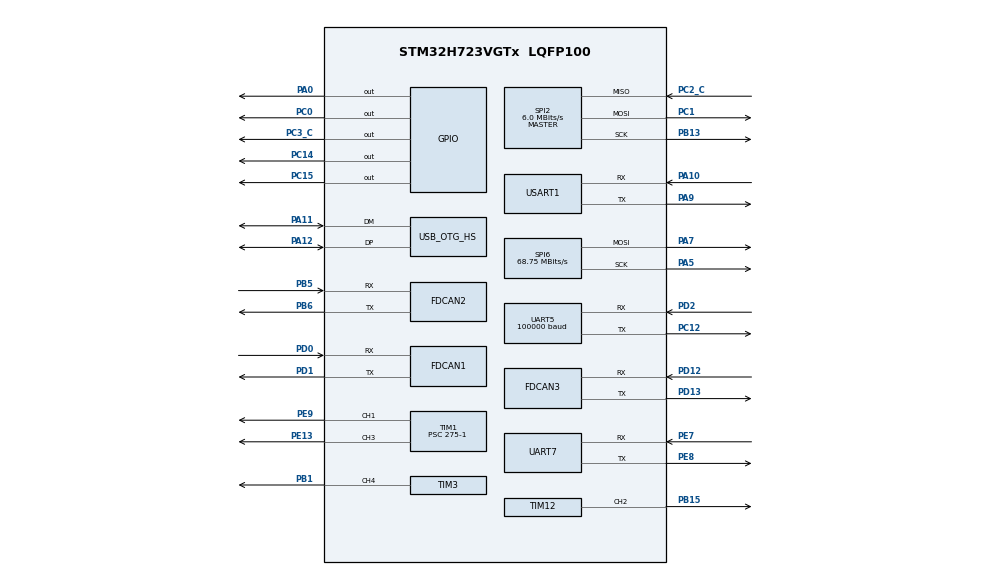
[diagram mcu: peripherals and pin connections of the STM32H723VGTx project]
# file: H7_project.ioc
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Bdma.Request0=SPI6_TX
Bdma.RequestsNb=1
Bdma.SPI6_TX.0.Direction=DMA_MEMORY_TO_PERIPH
Bdma.SPI6_TX.0.EventEnable=DISABLE
Bdma.SPI6_TX.0.Instance=BDMA_Channel0
Bdma.SPI6_TX.0.MemDataAlignment=DMA_MDATAALIGN_BYTE
Bdma.SPI6_TX.0.MemInc=DMA_MINC_ENABLE
Bdma.SPI6_TX.0.Mode=DMA_NORMAL
Bdma.SPI6_TX.0.PeriphDataAlignment=DMA_PDATAALIGN_BYTE
Bdma.SPI6_TX.0.PeriphInc=DMA_PINC_DISABLE
Bdma.SPI6_TX.0.Polarity=HAL_DMAMUX_REQ_GEN_RISING
Bdma.SPI6_TX.0.Priority=DMA_PRIORITY_VERY_HIGH
Bdma.SPI6_TX.0.RequestNumber=1
Bdma.SPI6_TX.0.SignalID=NONE
Bdma.SPI6_TX.0.SyncEnable=DISABLE
Bdma.SPI6_TX.0.SyncPolarity=HAL_DMAMUX_SYNC_NO_EVENT
Bdma.SPI6_TX.0.SyncRequestNumber=1
Bdma.SPI6_TX.0.SyncSignalID=NONE
CORTEX_M7.default_mode_Activation=1
Dma.Request0=UART5_RX
Dma.Request1=USART1_RX
Dma.Request2=USART1_TX
Dma.Request3=UART7_RX
Dma.Request4=UART7_TX
Dma.UART5_RX.0.Direction=DMA_PERIPH_TO_MEMORY
Dma.UART5_RX.0.EventEnable=DISABLE
Dma.UART5_RX.0.FIFOMode=DMA_FIFOMODE_DISABLE
Dma.UART5_RX.0.Instance=DMA1_Stream0
Dma.UART5_RX.0.MemDataAlignment=DMA_MDATAALIGN_BYTE
Dma.UART5_RX.0.MemInc=DMA_MINC_ENABLE
Dma.UART5_RX.0.Mode=DMA_CIRCULAR
Dma.UART5_RX.0.PeriphDataAlignment=DMA_PDATAALIGN_BYTE
Dma.UART5_RX.0.PeriphInc=DMA_PINC_DISABLE
Dma.UART5_RX.0.Polarity=HAL_DMAMUX_REQ_GEN_RISING
Dma.UART5_RX.0.Priority=DMA_PRIORITY_VERY_HIGH
Dma.UART5_RX.0.RequestNumber=1
Dma.UART5_RX.0.SignalID=NONE
Dma.UART5_RX.0.SyncEnable=DISABLE
Dma.UART5_RX.0.SyncPolarity=HAL_DMAMUX_SYNC_NO_EVENT
Dma.UART5_RX.0.SyncRequestNumber=1
Dma.UART5_RX.0.SyncSignalID=NONE
Dma.UART7_RX.3.Direction=DMA_PERIPH_TO_MEMORY
Dma.UART7_RX.3.EventEnable=DISABLE
Dma.UART7_RX.3.FIFOMode=DMA_FIFOMODE_DISABLE
Dma.UART7_RX.3.Instance=DMA1_Stream1
Dma.UART7_RX.3.MemDataAlignment=DMA_MDATAALIGN_BYTE
Dma.UART7_RX.3.MemInc=DMA_MINC_ENABLE
Dma.UART7_RX.3.Mode=DMA_CIRCULAR
Dma.UART7_RX.3.PeriphDataAlignment=DMA_PDATAALIGN_BYTE
Dma.UART7_RX.3.PeriphInc=DMA_PINC_DISABLE
Dma.UART7_RX.3.Polarity=HAL_DMAMUX_REQ_GEN_RISING
Dma.UART7_RX.3.Priority=DMA_PRIORITY_LOW
Dma.UART7_RX.3.RequestNumber=1
Dma.UART7_RX.3.SignalID=NONE
Dma.UART7_RX.3.SyncEnable=DISABLE
Dma.UART7_RX.3.SyncPolarity=HAL_DMAMUX_SYNC_NO_EVENT
Dma.UART7_RX.3.SyncRequestNumber=1
Dma.UART7_RX.3.SyncSignalID=NONE
Dma.UART7_TX.4.Direction=DMA_MEMORY_TO_PERIPH
Dma.UART7_TX.4.EventEnable=DISABLE
Dma.UART7_TX.4.FIFOMode=DMA_FIFOMODE_DISABLE
Dma.UART7_TX.4.Instance=DMA1_Stream3
Dma.UART7_TX.4.MemDataAlignment=DMA_MDATAALIGN_BYTE
Dma.UART7_TX.4.MemInc=DMA_MINC_ENABLE
Dma.UART7_TX.4.Mode=DMA_NORMAL
Dma.UART7_TX.4.PeriphDataAlignment=DMA_PDATAALIGN_BYTE
Dma.UART7_TX.4.PeriphInc=DMA_PINC_DISABLE
Dma.UART7_TX.4.Polarity=HAL_DMAMUX_REQ_GEN_RISING
Dma.UART7_TX.4.Priority=DMA_PRIORITY_LOW
Dma.UART7_TX.4.RequestNumber=1
Dma.UART7_TX.4.SignalID=NONE
Dma.UART7_TX.4.SyncEnable=DISABLE
Dma.UART7_TX.4.SyncPolarity=HAL_DMAMUX_SYNC_NO_EVENT
Dma.UART7_TX.4.SyncRequestNumber=1
Dma.UART7_TX.4.SyncSignalID=NONE
Dma.USART1_RX.1.Direction=DMA_PERIPH_TO_MEMORY
Dma.USART1_RX.1.EventEnable=DISABLE
Dma.USART1_RX.1.FIFOMode=DMA_FIFOMODE_DISABLE
Dma.USART1_RX.1.Instance=DMA1_Stream2
Dma.USART1_RX.1.MemDataAlignment=DMA_MDATAALIGN_BYTE
Dma.USART1_RX.1.MemInc=DMA_MINC_ENABLE
Dma.USART1_RX.1.Mode=DMA_CIRCULAR
Dma.USART1_RX.1.PeriphDataAlignment=DMA_PDATAALIGN_BYTE
Dma.USART1_RX.1.PeriphInc=DMA_PINC_DISABLE
Dma.USART1_RX.1.Polarity=HAL_DMAMUX_REQ_GEN_RISING
Dma.USART1_RX.1.Priority=DMA_PRIORITY_VERY_HIGH
Dma.USART1_RX.1.RequestNumber=1
Dma.USART1_RX.1.SignalID=NONE
Dma.USART1_RX.1.SyncEnable=DISABLE
Dma.USART1_RX.1.SyncPolarity=HAL_DMAMUX_SYNC_NO_EVENT
Dma.USART1_RX.1.SyncRequestNumber=1
Dma.USART1_RX.1.SyncSignalID=NONE
Dma.USART1_TX.2.Direction=DMA_MEMORY_TO_PERIPH
Dma.USART1_TX.2.EventEnable=DISABLE
Dma.USART1_TX.2.FIFOMode=DMA_FIFOMODE_DISABLE
Dma.USART1_TX.2.Instance=DMA1_Stream4
Dma.USART1_TX.2.MemDataAlignment=DMA_MDATAALIGN_BYTE
Dma.USART1_TX.2.MemInc=DMA_MINC_ENABLE
Dma.USART1_TX.2.Mode=DMA_NORMAL
Dma.USART1_TX.2.PeriphDataAlignment=DMA_PDATAALIGN_BYTE
Dma.USART1_TX.2.PeriphInc=DMA_PINC_DISABLE
Dma.USART1_TX.2.Polarity=HAL_DMAMUX_REQ_GEN_RISING
Dma.USART1_TX.2.Priority=DMA_PRIORITY_HIGH
Dma.USART1_TX.2.RequestNumber=1
Dma.USART1_TX.2.SignalID=NONE
Dma.USART1_TX.2.SyncEnable=DISABLE
Dma.USART1_TX.2.SyncPolarity=HAL_DMAMUX_SYNC_NO_EVENT
Dma.USART1_TX.2.SyncRequestNumber=1
Dma.USART1_TX.2.SyncSignalID=NONE
FDCAN1.CalculateBaudRateNominal=1000000
FDCAN1.CalculateTimeBitNominal=1000
FDCAN1.CalculateTimeQuantumNominal=62.5
FDCAN1.DataPrescaler=3
FDCAN1.DataTimeSeg1=7
FDCAN1.DataTimeSeg2=8
FDCAN1.NominalPrescaler=3
FDCAN1.NominalTimeSeg1=7
FDCAN1.NominalTimeSeg2=8
FDCAN1.RxFifo0ElmtsNbr=8
FDCAN1.StdFiltersNbr=1
FDCAN1.TxFifoQueueElmtsNbr=8
FDCAN2.CalculateBaudRateNominal=1000000
FDCAN2.CalculateTimeBitNominal=1000
FDCAN2.CalculateTimeQuantumNominal=62.5
FDCAN2.DataPrescaler=3
FDCAN2.DataTimeSeg1=7
FDCAN2.DataTimeSeg2=8
FDCAN2.MessageRAMOffset=800
FDCAN2.NominalPrescaler=3
FDCAN2.NominalTimeSeg1=7
FDCAN2.NominalTimeSeg2=8
FDCAN2.RxFifo0ElmtsNbr=8
FDCAN2.StdFiltersNbr=1
FDCAN2.TxFifoQueueElmtsNbr=8
FDCAN3.CalculateBaudRateNominal=1000000
FDCAN3.CalculateTimeBitNominal=1000
FDCAN3.CalculateTimeQuantumNominal=62.5
FDCAN3.DataPrescaler=3
FDCAN3.DataTimeSeg1=7
FDCAN3.DataTimeSeg2=8
FDCAN3.MessageRAMOffset=1600
FDCAN3.NominalPrescaler=3
FDCAN3.NominalTimeSeg1=7
FDCAN3.NominalTimeSeg2=8
FDCAN3.RxFifo1ElmtsNbr=8
FDCAN3.StdFiltersNbr=1
FDCAN3.TxFifoQueueElmtsNbr=8
Mcu.Family=STM32H7
Mcu.Name=STM32H723VGTx
Mcu.Package=LQFP100
NVIC.BDMA_Channel0_IRQn=true\:0\:0\:false\:false\:true\:false\:true\:true
NVIC.DMA1_Stream0_IRQn=true\:0\:0\:false\:false\:true\:false\:true\:true
NVIC.DMA1_Stream1_IRQn=true\:0\:0\:false\:false\:true\:false\:true\:true
NVIC.DMA1_Stream2_IRQn=true\:0\:0\:false\:false\:true\:false\:true\:true
NVIC.DMA1_Stream3_IRQn=true\:0\:0\:false\:false\:true\:false\:true\:true
NVIC.DMA1_Stream4_IRQn=true\:0\:0\:false\:false\:true\:false\:true\:true
NVIC.FDCAN1_IT0_IRQn=true\:1\:0\:true\:false\:true\:true\:true\:true
NVIC.FDCAN2_IT0_IRQn=true\:1\:0\:true\:false\:true\:true\:true\:true
NVIC.FDCAN3_IT1_IRQn=true\:1\:0\:true\:false\:true\:true\:true\:true
NVIC.OTG_HS_IRQn=true\:0\:0\:false\:false\:true\:true\:true\:true
NVIC.PriorityGroup=NVIC_PRIORITYGROUP_4
NVIC.SPI6_IRQn=true\:0\:0\:false\:false\:true\:false\:true\:true
NVIC.TIM2_IRQn=true\:0\:0\:false\:false\:true\:true\:true\:true
NVIC.TIM6_DAC_IRQn=true\:2\:0\:true\:false\:true\:true\:true\:true
NVIC.UART5_IRQn=true\:0\:0\:false\:false\:true\:true\:true\:true
NVIC.UART7_IRQn=true\:0\:0\:false\:false\:true\:true\:true\:true
NVIC.USART1_IRQn=true\:0\:0\:false\:false\:true\:false\:true\:true
PA0.Signal=GPIO_Output
PA10.Mode=Asynchronous
PA10.Signal=USART1_RX
PA11.Mode=Device_Only_FS
PA11.Signal=USB_OTG_HS_DM
PA12.Mode=Device_Only_FS
PA12.Signal=USB_OTG_HS_DP
PA13(JTMS/SWDIO).Mode=Serial_Wire
PA13(JTMS/SWDIO).Signal=DEBUG_JTMS-SWDIO
PA14(JTCK/SWCLK).Mode=Serial_Wire
PA14(JTCK/SWCLK).Signal=DEBUG_JTCK-SWCLK
PA5.Mode=TX_Only_Simplex_Unidirect_Master
PA5.Signal=SPI6_SCK
PA7.Mode=TX_Only_Simplex_Unidirect_Master
PA7.Signal=SPI6_MOSI
PA9.Mode=Asynchronous
PA9.Signal=USART1_TX
PB1.Signal=S_TIM3_CH4
PB13.Mode=Full_Duplex_Master
PB13.Signal=SPI2_SCK
PB15.Signal=S_TIM12_CH2
PB5.Mode=FDCAN_Activate
PB5.Signal=FDCAN2_RX
PB6.Mode=FDCAN_Activate
PB6.Signal=FDCAN2_TX
PC0.GPIO_Speed=GPIO_SPEED_FREQ_VERY_HIGH
PC0.Signal=GPIO_Output
PC1.Mode=Full_Duplex_Master
PC1.Signal=SPI2_MOSI
PC12.Mode=Asynchronous
PC12.Signal=UART5_TX
PC14-OSC32_IN.Signal=GPIO_Output
PC15-OSC32_OUT.Signal=GPIO_Output
PC2_C.Mode=Full_Duplex_Master
PC2_C.Signal=SPI2_MISO
PC3_C.GPIO_Speed=GPIO_SPEED_FREQ_VERY_HIGH
PC3_C.Signal=GPIO_Output
PD0.Mode=FDCAN_Activate
PD0.Signal=FDCAN1_RX
PD1.Mode=FDCAN_Activate
PD1.Signal=FDCAN1_TX
PD12.Mode=FDCAN_Activate
PD12.Signal=FDCAN3_RX
PD13.Mode=FDCAN_Activate
PD13.Signal=FDCAN3_TX
PD2.Mode=Asynchronous
PD2.Signal=UART5_RX
PE13.Signal=S_TIM1_CH3
PE7.Mode=Asynchronous
PE7.Signal=UART7_RX
PE8.Mode=Asynchronous
PE8.Signal=UART7_TX
PE9.Signal=S_TIM1_CH1
PH0-OSC_IN.Mode=HSE-External-Oscillator
PH0-OSC_IN.Signal=RCC_OSC_IN
PH1-OSC_OUT.Mode=HSE-External-Oscillator
PH1-OSC_OUT.Signal=RCC_OSC_OUT
ProjectManager.HeapSize=0x800
ProjectManager.StackSize=0x800
ProjectManager.TargetToolchain=CMake
RCC.ADCFreq_Value=96000000
RCC.APB1Freq_Value=137500000
RCC.APB2Freq_Value=137500000
RCC.APB3Freq_Value=137500000
RCC.APB4Freq_Value=137500000
RCC.CortexFreq_Value=550000000
RCC.D1PPRE=RCC_APB3_DIV2
RCC.D2PPRE1=RCC_APB1_DIV2
RCC.D2PPRE2=RCC_APB2_DIV2
RCC.D3PPRE=RCC_APB4_DIV2
RCC.DIVM1=3
RCC.DIVM2=16
RCC.DIVM3=16
RCC.DIVN1=68
RCC.DIVN2=128
RCC.DIVN3=128
RCC.DIVP1=1
RCC.DIVQ2=4
RCC.DIVQ3=4
RCC.FDCANCLockSelection=RCC_FDCANCLKSOURCE_PLL2
RCC.HCLKFreq_Value=275000000
RCC.HPRE=RCC_HCLK_DIV2
RCC.HSE_VALUE=24000000
RCC.PLL2FRACN=0
RCC.PLLFRACN=6144
RCC.PLLSourceVirtual=RCC_PLLSOURCE_HSE
RCC.SPI123CLockSelection=RCC_SPI123CLKSOURCE_PLL2
RCC.SYSCLKFreq_VALUE=550000000
RCC.SYSCLKSource=RCC_SYSCLKSOURCE_PLLCLK
RCC.USART234578CLockSelection=RCC_USART234578CLKSOURCE_PLL2
RCC.USBCLockSelection=RCC_USBCLKSOURCE_PLL3
RCC.USBFreq_Value=48000000
SH.S_TIM12_CH2.0=TIM12_CH2,PWM Generation2 CH2
SH.S_TIM1_CH1.0=TIM1_CH1,PWM Generation1 CH1
SH.S_TIM1_CH3.0=TIM1_CH3,PWM Generation3 CH3
SH.S_TIM3_CH4.0=TIM3_CH4,Output Compare4 CH4
SPI2.BaudRatePrescaler=SPI_BAUDRATEPRESCALER_16
SPI2.CalculateBaudRate=6.0 MBits/s
SPI2.DataSize=SPI_DATASIZE_8BIT
SPI2.Direction=SPI_DIRECTION_2LINES
SPI2.Mode=SPI_MODE_MASTER
SPI2.VirtualType=VM_MASTER
SPI6.CalculateBaudRate=68.75 MBits/s
SPI6.Direction=SPI_DIRECTION_2LINES_TXONLY
SPI6.Mode=SPI_MODE_MASTER
SPI6.VirtualType=VM_MASTER
TIM1.Channel-PWM\ Generation1\ CH1=TIM_CHANNEL_1
TIM1.Channel-PWM\ Generation3\ CH3=TIM_CHANNEL_3
TIM1.Period=500-1
TIM1.Prescaler=275-1
TIM12.Channel-PWM\ Generation2\ CH2=TIM_CHANNEL_2
TIM12.Period=1000-1
TIM12.Prescaler=275-1
TIM2.AutoReloadPreload=TIM_AUTORELOAD_PRELOAD_DISABLE
TIM2.Period=275-1
TIM2.Prescaler=1000-1
TIM3.Channel-Output\ Compare4\ CH4=TIM_CHANNEL_4
TIM6.Period=1000-1
TIM6.Prescaler=275-1
UART5.BaudRate=100000
UART5.Mode=MODE_RX
UART5.Parity=PARITY_EVEN
UART5.WordLength=WORDLENGTH_9B
USART1.VirtualMode-Asynchronous=VM_ASYNC
USB_DEVICE.CLASS_NAME_HS=CDC
USB_DEVICE.VirtualMode=Cdc
USB_DEVICE.VirtualModeHS=Cdc_HS
USB_OTG_HS.VirtualMode-Device_Only_FS=Device_Only_FS
VP_CORDIC_VS_CORDIC.Mode=CORDIC_Activate
VP_IWDG1_VS_IWDG.Mode=IWDG_Activate
VP_MEMORYMAP_VS_MEMORYMAP.Mode=CurAppReg
VP_TIM12_VS_ClockSourceINT.Mode=Internal
VP_TIM1_VS_ClockSourceINT.Mode=Internal
VP_TIM2_VS_ClockSourceINT.Mode=Internal
VP_TIM3_VS_ClockSourceINT.Mode=Internal
VP_TIM6_VS_ClockSourceINT.Mode=Enable_Timer
VP_USB_DEVICE_VS_USB_DEVICE_CDC_HS.Mode=CDC_HS
board=custom

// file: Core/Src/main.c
/* USER CODE BEGIN Header */
/**
  ******************************************************************************
  * @file           : main.c
  * @brief          : Main program body
  ******************************************************************************
  * @attention
  *
  * Copyright (c) 2025 STMicroelectronics.
  * All rights reserved.
  *
  * This software is licensed under terms that can be found in the LICENSE file
  * in the root directory of this software component.
  * If no LICENSE file comes with this software, it is provided AS-IS.
  *
  ******************************************************************************
  */
/* USER CODE END Header */
#include "main.h"
#include "bdma.h"
#include "cordic.h"
#include "dma.h"
#include "fdcan.h"
#include "iwdg.h"
#include "spi.h"
#include "tim.h"
#include "usart.h"
#include "usb_device.h"
#include "gpio.h"

/* USER CODE BEGIN Includes */
#include "MotorControl.hpp"
/* USER CODE END Includes */

void SystemClock_Config(void);
void PeriphCommonClock_Config(void);
static void MPU_Config(void);

int main(void)
{

  /* MPU Configuration--------------------------------------------------------*/
  MPU_Config();

  /* MCU Configuration--------------------------------------------------------*/

  /* Reset of all peripherals, Initializes the Flash interface and the Systick. */
  HAL_Init();

  /* Configure the system clock */
  SystemClock_Config();

  /* Configure the peripherals common clocks */
  PeriphCommonClock_Config();

  /* Initialize all configured peripherals */
  MX_GPIO_Init();
  MX_DMA_Init();
  MX_BDMA_Init();
  MX_FDCAN1_Init();
  MX_FDCAN2_Init();
  MX_FDCAN3_Init();
  MX_IWDG1_Init();
  MX_SPI2_Init();
  MX_SPI6_Init();
  MX_TIM2_Init();
  MX_TIM3_Init();
  MX_TIM6_Init();
  MX_TIM12_Init();
  MX_UART5_Init();
  MX_USART1_UART_Init();
  MX_USB_DEVICE_Init();
  MX_CORDIC_Init();
  MX_TIM1_Init();
  MX_UART7_Init();
  /* USER CODE BEGIN 2 */
  MainInit();
  /* USER CODE END 2 */

  /* Infinite loop */
  while (1)
  {

  }
}

void SystemClock_Config(void)
{
  RCC_OscInitTypeDef RCC_OscInitStruct = {0};
  RCC_ClkInitTypeDef RCC_ClkInitStruct = {0};

  /** Supply configuration update enable
  */
  HAL_PWREx_ConfigSupply(PWR_LDO_SUPPLY);

  /** Configure the main internal regulator output voltage
  */
  __HAL_PWR_VOLTAGESCALING_CONFIG(PWR_REGULATOR_VOLTAGE_SCALE0);

  while(!__HAL_PWR_GET_FLAG(PWR_FLAG_VOSRDY)) {}

  /** Initializes the RCC Oscillators according to the specified parameters
  * in the RCC_OscInitTypeDef structure.
  */
  RCC_OscInitStruct.OscillatorType = RCC_OSCILLATORTYPE_LSI|RCC_OSCILLATORTYPE_HSE;
  RCC_OscInitStruct.HSEState = RCC_HSE_ON;
  RCC_OscInitStruct.LSIState = RCC_LSI_ON;
  RCC_OscInitStruct.PLL.PLLState = RCC_PLL_ON;
  RCC_OscInitStruct.PLL.PLLSource = RCC_PLLSOURCE_HSE;
  RCC_OscInitStruct.PLL.PLLM = 3;
  RCC_OscInitStruct.PLL.PLLN = 68;
  RCC_OscInitStruct.PLL.PLLP = 1;
  RCC_OscInitStruct.PLL.PLLQ = 2;
  RCC_OscInitStruct.PLL.PLLR = 2;
  RCC_OscInitStruct.PLL.PLLRGE = RCC_PLL1VCIRANGE_3;
  RCC_OscInitStruct.PLL.PLLVCOSEL = RCC_PLL1VCOWIDE;
  RCC_OscInitStruct.PLL.PLLFRACN = 6144;
  if (HAL_RCC_OscConfig(&RCC_OscInitStruct) != HAL_OK)
  {
    Error_Handler();
  }

  /** Initializes the CPU, AHB and APB buses clocks
  */
  RCC_ClkInitStruct.ClockType = RCC_CLOCKTYPE_HCLK|RCC_CLOCKTYPE_SYSCLK
                              |RCC_CLOCKTYPE_PCLK1|RCC_CLOCKTYPE_PCLK2
                              |RCC_CLOCKTYPE_D3PCLK1|RCC_CLOCKTYPE_D1PCLK1;
  RCC_ClkInitStruct.SYSCLKSource = RCC_SYSCLKSOURCE_PLLCLK;
  RCC_ClkInitStruct.SYSCLKDivider = RCC_SYSCLK_DIV1;
  RCC_ClkInitStruct.AHBCLKDivider = RCC_HCLK_DIV2;
  RCC_ClkInitStruct.APB3CLKDivider = RCC_APB3_DIV2;
  RCC_ClkInitStruct.APB1CLKDivider = RCC_APB1_DIV2;
  RCC_ClkInitStruct.APB2CLKDivider = RCC_APB2_DIV2;
  RCC_ClkInitStruct.APB4CLKDivider = RCC_APB4_DIV2;

  if (HAL_RCC_ClockConfig(&RCC_ClkInitStruct, FLASH_LATENCY_3) != HAL_OK)
  {
    Error_Handler();
  }
}

void PeriphCommonClock_Config(void)
{
  RCC_PeriphCLKInitTypeDef PeriphClkInitStruct = {0};

  /** Initializes the peripherals clock
  */
  PeriphClkInitStruct.PeriphClockSelection = RCC_PERIPHCLK_SPI2|RCC_PERIPHCLK_UART5
                              |RCC_PERIPHCLK_FDCAN|RCC_PERIPHCLK_UART7;
  PeriphClkInitStruct.PLL2.PLL2M = 16;
  PeriphClkInitStruct.PLL2.PLL2N = 128;
  PeriphClkInitStruct.PLL2.PLL2P = 2;
  PeriphClkInitStruct.PLL2.PLL2Q = 4;
  PeriphClkInitStruct.PLL2.PLL2R = 2;
  PeriphClkInitStruct.PLL2.PLL2RGE = RCC_PLL2VCIRANGE_0;
  PeriphClkInitStruct.PLL2.PLL2VCOSEL = RCC_PLL2VCOMEDIUM;
  PeriphClkInitStruct.PLL2.PLL2FRACN = 0;
  PeriphClkInitStruct.Spi123ClockSelection = RCC_SPI123CLKSOURCE_PLL2;
  PeriphClkInitStruct.FdcanClockSelection = RCC_FDCANCLKSOURCE_PLL2;
  PeriphClkInitStruct.Usart234578ClockSelection = RCC_USART234578CLKSOURCE_PLL2;
  if (HAL_RCCEx_PeriphCLKConfig(&PeriphClkInitStruct) != HAL_OK)
  {
    Error_Handler();
  }
}

 /* MPU Configuration */

void MPU_Config(void)
{
  MPU_Region_InitTypeDef MPU_InitStruct = {0};

  /* Disables the MPU */
  HAL_MPU_Disable();

  /** Initializes and configures the Region and the memory to be protected
  */
  MPU_InitStruct.Enable = MPU_REGION_ENABLE;
  MPU_InitStruct.Number = MPU_REGION_NUMBER0;
  MPU_InitStruct.BaseAddress = 0x0;
  MPU_InitStruct.Size = MPU_REGION_SIZE_4GB;
  MPU_InitStruct.SubRegionDisable = 0x87;
  MPU_InitStruct.TypeExtField = MPU_TEX_LEVEL0;
  MPU_InitStruct.AccessPermission = MPU_REGION_NO_ACCESS;
  MPU_InitStruct.DisableExec = MPU_INSTRUCTION_ACCESS_DISABLE;
  MPU_InitStruct.IsShareable = MPU_ACCESS_SHAREABLE;
  MPU_InitStruct.IsCacheable = MPU_ACCESS_NOT_CACHEABLE;
  MPU_InitStruct.IsBufferable = MPU_ACCESS_NOT_BUFFERABLE;

  HAL_MPU_ConfigRegion(&MPU_InitStruct);
  /* Enables the MPU */
  HAL_MPU_Enable(MPU_PRIVILEGED_DEFAULT);

}

void Error_Handler(void)
{
  __disable_irq();
  while (1)
  {
  }
}
